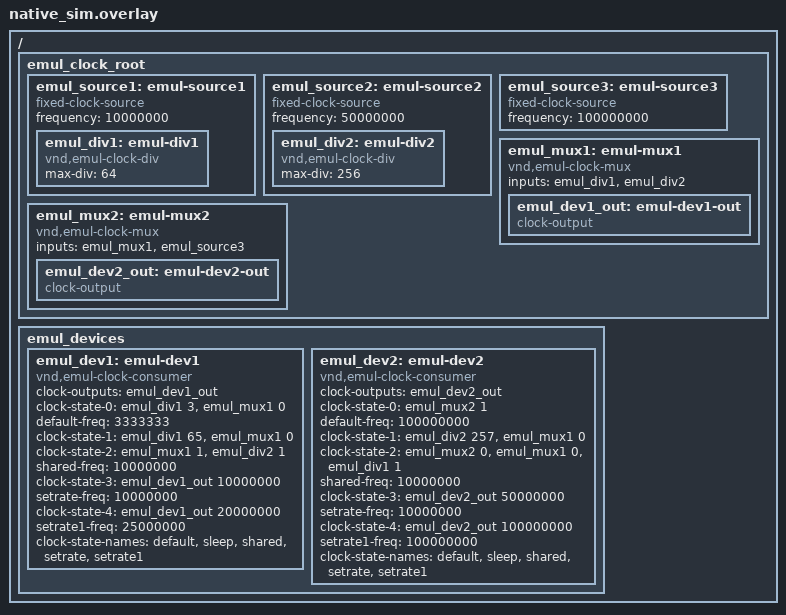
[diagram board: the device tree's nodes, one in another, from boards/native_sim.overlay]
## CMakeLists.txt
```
# SPDX-License-Identifier: Apache-2.0

cmake_minimum_required(VERSION 3.20.0)

find_package(Zephyr REQUIRED HINTS $ENV{ZEPHYR_BASE})
project(clock_mgmt_api)

FILE(GLOB app_sources src/*.c)
FILE(GLOB clock_sources src/clock_drivers/*.c)
target_sources(app PRIVATE ${app_sources} ${clock_sources})
```

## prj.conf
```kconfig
CONFIG_ZTEST=y
CONFIG_CLOCK_MGMT=y
CONFIG_CLOCK_MGMT_NOTIFY=y
CONFIG_CLOCK_MGMT_SET_RATE=y
```

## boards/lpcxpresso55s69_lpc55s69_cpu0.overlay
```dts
/*
 * Copyright 2024 NXP
 *
 * SPDX-License-Identifier: Apache-2.0
 */

/* Clock CPU from FROHF, since we will use the PLLs within our testcases */
&cpu0 {
	clock-state-0 = <&system_clock 96000000>;
	clock-state-names = "default";
};

/* Disable the SD controller- we are using its clock for this test */
&sdif {
	status = "disabled";
};

/ {
	/* Emulated device clock consumers */
	emul_devices {
		emul_dev1: emul-dev1 {
			compatible = "vnd,emul-clock-consumer";
			clock-outputs = <&clkout_clock>;
			/* Expect a clock frequency of 500 KHz */
			clock-state-0 = <&xtal32m 1 &clk_in_en 1 &pll0clksel 1
					&pll0_pdec 4 &pll0_directo 0
					&pll0 512000000 8 256 0 31 31 0 0 0
					&pll1_bypass 0 &clkoutsel 1
					&clkoutdiv 256>;
			default-freq = <500000>;
			/* Expect error when applying this invalid state */
			clock-state-1 = <&clkoutsel 10>;
			/* Expect notification on first device only,
			 * as sdioclksel is not selecting pll0 as an input.
			 * After reconfiguring PLL0 from emul_dev2, output
			 * frequency will be 25.5 MHz
			 */
			clock-state-2 = <&pll0_pdec 8 &pll0 401000000 4 0
					0 4 3 1 3363831808 0 &clkoutdiv 2>;
			shared-freq = <25500000>;
			/* Request 55MHz. We expect pll0 to be used to
			 * produce this clock rate.
			 */
			clock-state-3 = <&clkout_clock 55000000>;
			setrate-freq = <55000000>;
			/* Request 96Mhz. We should be switched to
			 * fro_hf, which will produce 96MHz
			 */
			clock-state-4 = <&clkout_clock 96000000>;
			setrate1-freq = <96000000>;
			clock-state-names = "default", "sleep",
					"shared", "setrate", "setrate1";
		};

		emul_dev2: emul-dev2 {
			compatible = "vnd,emul-clock-consumer";
			clock-outputs = <&sdio_clock>;
			/* Expect a clock frequency of 48 MHz */
			clock-state-0 = <&fro_12m 1 &pll1clksel 0
					&pll1_pdec 4 &pll1_directo 0
					&pll1 384000000 4 128 0 62 31
					&pll1_bypass 0 &sdioclksel 5
					&sdioclkdiv 2>;
			default-freq = <48000000>;
			/* Expect error when applying this invalid state */
			clock-state-1 = <&sdioclksel 8>;
			/* Expect notification on both devices with this state.
			 * frequency should be 25.5 MHz for each
			 */
			clock-state-2 = <&pll0_pdec 8 &pll0 408000000 4 0
					0 4 3 1 3422552064 0 &sdioclkdiv 2
					&sdioclksel 1>;
			shared-freq = <25500000>;
			/* Request 25.10MHz. The best source for this would be
			 * pll0, but since it is locked we
			 * expect to be forced to use pll1
			 */
			clock-state-3 = <&sdio_clock 25100000>;
			setrate-freq = <27466668>;
			/* Request 25.5MHz again. PLL0 is no longer locked, so
			 * we should get this frequency now
			 */
			clock-state-4 = <&sdio_clock 25500000>;
			setrate1-freq = <25500000>;
			clock-state-names = "default", "sleep",
					"shared", "setrate", "setrate1";
		};
	};
};
```

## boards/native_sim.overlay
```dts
/*
 * Copyright 2024 NXP
 *
 * SPDX-License-Identifier: Apache-2.0
 */

/*
 * Define clock tree with emulated clock nodes.
 * These node labels are chosen so that they won't conflict with SOC clock
 * tree nodelabels. The clock driver implementations used by this tree are
 * stored within the test itself
 */

/ {
	emul_clock_root {
		emul_source1: emul-source1 {
			compatible = "fixed-clock-source";
			frequency = <10000000>;
			#clock-cells = <0>;

			emul_div1: emul-div1 {
				compatible = "vnd,emul-clock-div";
				max-div = <64>;
				#clock-cells = <1>;
			};
		};

		emul_source2: emul-source2 {
			compatible = "fixed-clock-source";
			frequency = <50000000>;
			#clock-cells = <0>;

			emul_div2: emul-div2 {
				compatible = "vnd,emul-clock-div";
				max-div = <256>;
				#clock-cells = <1>;
			};
		};

		emul_source3: emul-source3 {
			compatible = "fixed-clock-source";
			frequency = <100000000>;
			#clock-cells = <0>;
		};

		emul_mux1: emul-mux1 {
			compatible = "vnd,emul-clock-mux";
			inputs = <&emul_div1 &emul_div2>;
			#clock-cells = <1>;

			emul_dev1_out: emul-dev1-out {
				compatible = "clock-output";
				#clock-cells = <1>;
			};
		};

		emul_mux2: emul-mux2 {
			compatible = "vnd,emul-clock-mux";
			inputs = <&emul_mux1 &emul_source3>;
			#clock-cells = <1>;

			emul_dev2_out: emul-dev2-out {
				compatible = "clock-output";
				#clock-cells = <1>;
			};
		};
	};

	/* Emulated device clock consumers */
	emul_devices {
		emul_dev1: emul-dev1 {
			compatible = "vnd,emul-clock-consumer";
			clock-outputs = <&emul_dev1_out>;
			/* Expect a clock frequency of 3.333333 MHz */
			clock-state-0 = <&emul_div1 3 &emul_mux1 0>;
			default-freq = <3333333>;
			/* Expect error when applying this invalid state */
			clock-state-1 = <&emul_div1 65 &emul_mux1 0>;
			/* Expect notification on first device only,
			 * as emul_mux2 is not selecting emul_mux1 as an input.
			 * frequency should be 50 MHz
			 */
			clock-state-2 = <&emul_mux1 1 &emul_div2 1>;
			shared-freq = <10000000>;
			/* Request 10MHz. We expect emul_source1 to be used to
			 * produce this clock rate.
			 */
			clock-state-3 = <&emul_dev1_out 10000000>;
			setrate-freq = <10000000>;
			/* Request 20MHz. We should be switched to
			 * emul_div2, which will produce 25Mhz
			 */
			clock-state-4 = <&emul_dev1_out 20000000>;
			setrate1-freq = <25000000>;
			clock-state-names = "default", "sleep",
					"shared", "setrate", "setrate1";
		};

		emul_dev2: emul-dev2 {
			compatible = "vnd,emul-clock-consumer";
			clock-outputs = <&emul_dev2_out>;
			/* Expect a clock frequency of 100 MHz */
			clock-state-0 = <&emul_mux2 1>;
			default-freq = <100000000>;
			/* Expect error when applying this invalid state */
			clock-state-1 = <&emul_div2 257 &emul_mux1 0>;
			/* Expect notification on both devices with this state.
			 * frequency should be 10 MHz for each
			 */
			clock-state-2 = <&emul_mux2 0 &emul_mux1 0 &emul_div1 1>;
			shared-freq = <10000000>;
			/* Request 50MHz. The best source for this would be
			 * emul_source2, but since emul_mux1 is locked we
			 * expect to be forced to use 10MHz
			 */
			clock-state-3 = <&emul_dev2_out 50000000>;
			setrate-freq = <10000000>;
			/* Request 100MHz. We should be switched to
			 * emul_source3.
			 */
			clock-state-4 = <&emul_dev2_out 100000000>;
			setrate1-freq = <100000000>;
			clock-state-names = "default", "sleep",
					"shared", "setrate", "setrate1";
		};
	};
};
```

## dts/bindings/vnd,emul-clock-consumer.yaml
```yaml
# Copyright 2024 NXP
#
# SPDX-License-Identifier: Apache-2.0

description: |
  Binding for emulated clock consumer device. This device is used in testing
  to verify that clock states are applied as expected.

compatible: "vnd,emul-clock-consumer"

include: [clock-device.yaml]

properties:
  default-freq:
    type: int
    required: true
    description: |
      Frequency this consumer expects to read when applying default clock
      management state

  shared-freq:
    type: int
    required: true
    description: |
      Frequency this consumer expects to read when applying shared clock
      management state

  setrate-freq:
    type: int
    required: true
    description: |
      Frequency this consumer expects to read when applying setrate clock
      management state

  setrate1-freq:
    type: int
    required: true
    description: |
      Frequency this consumer expects to read when applying setrate1 clock
      management state
```

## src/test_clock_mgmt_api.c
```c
/*
 * Copyright 2024 NXP
 *
 * SPDX-License-Identifier: Apache-2.0
 */
#include <zephyr/ztest.h>
#include <zephyr/drivers/clock_mgmt.h>
#include <zephyr/logging/log.h>

#include "clock_drivers/emul_clock_drivers.h"
LOG_MODULE_REGISTER(test);

/* Custom clock management states for this test */
#define CLOCK_MGMT_STATE_INVALID CLOCK_MGMT_STATE_SLEEP
#define CLOCK_MGMT_STATE_SHARED CLOCK_MGMT_STATE_PRIV_START
#define CLOCK_MGMT_STATE_SETRATE (CLOCK_MGMT_STATE_PRIV_START + 1)
#define CLOCK_MGMT_STATE_SETRATE1 (CLOCK_MGMT_STATE_PRIV_START + 2)

/* Define clock management states for both clock consumers */
CLOCK_MGMT_DEFINE(DT_NODELABEL(emul_dev1));
CLOCK_MGMT_DEFINE(DT_NODELABEL(emul_dev2));

/* Get references to each clock management state */
static const struct clock_mgmt *consumer1 =
	CLOCK_MGMT_DT_DEV_CONFIG_GET(DT_NODELABEL(emul_dev1));
static const struct clock_mgmt *consumer2 =
	CLOCK_MGMT_DT_DEV_CONFIG_GET(DT_NODELABEL(emul_dev2));

struct consumer_cb_data {
	uint32_t rate;
	bool signalled;
};

static struct consumer_cb_data consumer1_cb_data;
static struct consumer_cb_data consumer2_cb_data;

static int consumer_cb(uint8_t output_idx, uint32_t new_rate,
			const void *data)
{
	struct consumer_cb_data *cb_data = (struct consumer_cb_data *)data;

	cb_data->rate = new_rate;
	cb_data->signalled = true;
	return 0;
}

ZTEST(clock_mgmt_api, test_basic_state)
{
	int ret;

	/* Apply default clock states for both consumers, make sure
	 * that rates match what is expected
	 */
	TC_PRINT("Applying default clock states\n");

	ret = clock_mgmt_apply_state(consumer1, CLOCK_MGMT_STATE_DEFAULT);
	zassert_equal(ret, 0, "Failed to apply default clock management state");
	ret = clock_mgmt_get_rate(consumer1, CLOCK_MGMT_OUTPUT_DEFAULT);
	TC_PRINT("Consumer 1 default clock rate: %d\n", ret);
	zassert_equal(ret, DT_PROP(DT_NODELABEL(emul_dev1), default_freq),
		      "Consumer 1 has invalid clock rate");

	ret = clock_mgmt_apply_state(consumer2, CLOCK_MGMT_STATE_DEFAULT);
	zassert_equal(ret, 0, "Failed to apply default clock management state");
	ret = clock_mgmt_get_rate(consumer2, CLOCK_MGMT_OUTPUT_DEFAULT);
	TC_PRINT("Consumer 2 default clock rate: %d\n", ret);
	zassert_equal(ret, DT_PROP(DT_NODELABEL(emul_dev2), default_freq),
		      "Consumer 2 has invalid clock rate");
}

ZTEST(clock_mgmt_api, test_invalid_state)
{
	int ret;
	/* Apply invalid clock state, verify an error is returned */
	TC_PRINT("Try to apply invalid clock states\n");

	ret = clock_mgmt_apply_state(consumer1, CLOCK_MGMT_STATE_INVALID);
	zassert_not_equal(ret, 0, "Invalid state should return an error");
	ret = clock_mgmt_apply_state(consumer2, CLOCK_MGMT_STATE_INVALID);
	zassert_not_equal(ret, 0, "Invalid state should return an error");
}


ZTEST(clock_mgmt_api, test_shared_notification)
{
	int ret;
	/* Apply invalid clock state, verify an error is returned */
	TC_PRINT("Try to apply shared clock states\n");

	ret = clock_mgmt_set_callback(consumer1, consumer_cb,
				      &consumer1_cb_data);
	zassert_equal(ret, 0, "Could not install callback");
	ret = clock_mgmt_set_callback(consumer2, consumer_cb,
				      &consumer2_cb_data);
	zassert_equal(ret, 0, "Could not install callback");

	/* Reset clock tree to default state */
	ret = clock_mgmt_apply_state(consumer1, CLOCK_MGMT_STATE_DEFAULT);
	zassert_equal(ret, 0, "Failed to apply default clock management state");
	ret = clock_mgmt_apply_state(consumer2, CLOCK_MGMT_STATE_DEFAULT);
	zassert_equal(ret, 0, "Failed to apply default clock management state");
	/* Clear any old callback notifications */
	consumer1_cb_data.signalled = false;
	consumer2_cb_data.signalled = false;

	ret = clock_mgmt_apply_state(consumer1, CLOCK_MGMT_STATE_SHARED);
	zassert_equal(ret, 0, "Shared state should apply correctly");
	/* At this point only the first consumer should have a notification */
	zassert_true(consumer1_cb_data.signalled,
		     "Consumer 1 should have callback notification");
	zassert_false(consumer2_cb_data.signalled,
		      "Consumer 2 should not have callback notification");

	/* Clear any old callback notifications */
	consumer1_cb_data.signalled = false;
	consumer2_cb_data.signalled = false;
	ret = clock_mgmt_apply_state(consumer2, CLOCK_MGMT_STATE_SHARED);
	zassert_equal(ret, 0, "Shared state should apply correctly");
	zassert_true(consumer1_cb_data.signalled,
		     "Consumer 1 should have callback notification");
	zassert_true(consumer2_cb_data.signalled,
		     "Consumer 2 should have callback notification");
	/* Check rates */
	ret = clock_mgmt_get_rate(consumer1, CLOCK_MGMT_OUTPUT_DEFAULT);
	TC_PRINT("Consumer 1 shared clock rate: %d\n", ret);
	zassert_equal(ret, DT_PROP(DT_NODELABEL(emul_dev1), shared_freq),
		      "Consumer 1 has invalid clock rate");
	ret = clock_mgmt_get_rate(consumer2, CLOCK_MGMT_OUTPUT_DEFAULT);
	TC_PRINT("Consumer 2 shared clock rate: %d\n", ret);
	zassert_equal(ret, DT_PROP(DT_NODELABEL(emul_dev2), shared_freq),
		      "Consumer 2 has invalid clock rate");
}


ZTEST(clock_mgmt_api, test_setrate)
{
	int ret;
	/* Apply setrate clock state, verify frequencies */
	TC_PRINT("Try to apply setrate clock states\n");

	ret = clock_mgmt_apply_state(consumer1, CLOCK_MGMT_STATE_SETRATE);
	zassert_equal(ret, 0, "Failed to apply setrate clock management state");
	ret = clock_mgmt_apply_state(consumer2, CLOCK_MGMT_STATE_SETRATE);
	zassert_equal(ret, 0, "Failed to apply setrate clock management state");

	/* Check rates */
	ret = clock_mgmt_get_rate(consumer1, CLOCK_MGMT_OUTPUT_DEFAULT);
	TC_PRINT("Consumer 1 setrate clock rate: %d\n", ret);
	zassert_equal(ret, DT_PROP(DT_NODELABEL(emul_dev1), setrate_freq),
		      "Consumer 1 has invalid clock rate");
	ret = clock_mgmt_get_rate(consumer2, CLOCK_MGMT_OUTPUT_DEFAULT);
	TC_PRINT("Consumer 2 setrate clock rate: %d\n", ret);
	zassert_equal(ret, DT_PROP(DT_NODELABEL(emul_dev2), setrate_freq),
		      "Consumer 2 has invalid clock rate");

	/* Apply setrate1 clock state, verify frequencies */
	TC_PRINT("Try to apply setrate1 clock states\n");

	ret = clock_mgmt_apply_state(consumer1, CLOCK_MGMT_STATE_SETRATE1);
	zassert_equal(ret, 0, "Failed to apply setrate1 clock management state");
	ret = clock_mgmt_apply_state(consumer2, CLOCK_MGMT_STATE_SETRATE1);
	zassert_equal(ret, 0, "Failed to apply setrate1 clock management state");

	/* Check rates */
	ret = clock_mgmt_get_rate(consumer1, CLOCK_MGMT_OUTPUT_DEFAULT);
	TC_PRINT("Consumer 1 setrate1 clock rate: %d\n", ret);
	zassert_equal(ret, DT_PROP(DT_NODELABEL(emul_dev1), setrate1_freq),
		      "Consumer 1 has invalid clock rate");
	ret = clock_mgmt_get_rate(consumer2, CLOCK_MGMT_OUTPUT_DEFAULT);
	TC_PRINT("Consumer 2 setrate1 clock rate: %d\n", ret);
	zassert_equal(ret, DT_PROP(DT_NODELABEL(emul_dev2), setrate1_freq),
		      "Consumer 2 has invalid clock rate");
}

ZTEST_SUITE(clock_mgmt_api, NULL, NULL, NULL, NULL, NULL);
```
